# STM32H7R3xx register map
File version: 1.0
Registers are 32-bit, read-write, reset 0x0 unless marked. A register's access mark holds for its fields unless they carry their own. Offsets are from the block's base; [hi:lo] are bit positions; {n}, {i} and the like mark numbered series.

## HASH
Base 0x48020400
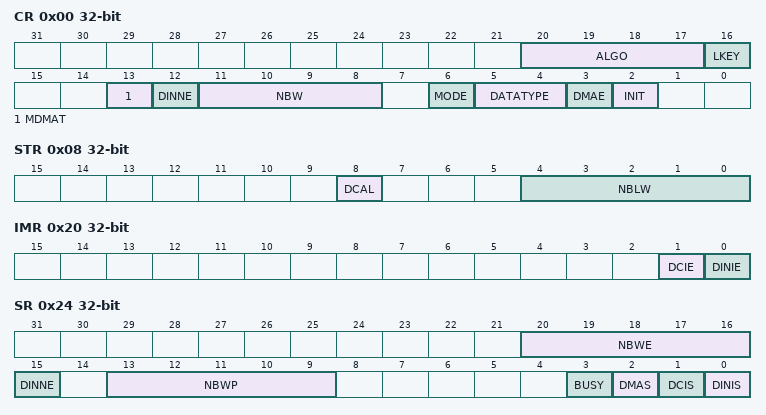
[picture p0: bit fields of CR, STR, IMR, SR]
0x00 CR — HASH control register
  [20:17] ALGO, [16] LKEY, [13] MDMAT, [12] DINNE, [11:8] NBW, [6] MODE, [5:4] DATATYPE, [3] DMAE, [2] INIT
0x04 DIN — HASH data input register
0x08 STR — HASH start register
  [8] DCAL, [4:0] NBLW
{0xC+4i} HR{i} (i=0..4) — HASH digest registers
0x20 IMR — HASH interrupt enable register
  [1] DCIE, [0] DINIE
0x24 SR — HASH status register
  [20:16] NBWE, [15] DINNE, [13:9] NBWP, [3] BUSY, [2] DMAS, [1] DCIS, [0] DINIS
{0xF8+4i} CSR[{i}] (i=0..102)
{0x310+4i} DIGEST_HR{i} (i=0..15) — HASH digest registers

## PKA — Public Key Accelerator (PKA)
Base 0x48022000
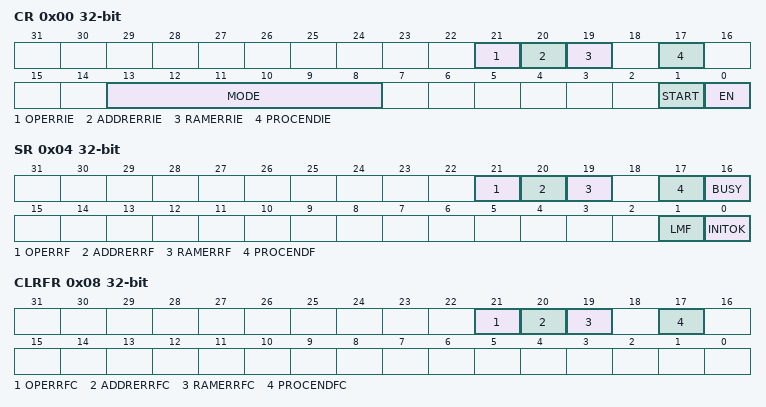
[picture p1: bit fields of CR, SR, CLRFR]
0x00 CR — PKA control register
  [21] OPERRIE — Operation Error interrupt enable
  [20] ADDRERRIE — Address error interrupt enable
  [19] RAMERRIE — RAM error interrupt enable
  [17] PROCENDIE — End of operation interrupt enable
  [13:8] MODE — MODE[5:0] PKA operation code
  [1] START — Start operation
  [0] EN — PKA enable
0x04 SR — PKA status register
  [21] OPERRF — PKA operation Error flag
  [20] ADDRERRF — Address error flag
  [19] RAMERRF — PKA RAM error flag
  [17] PROCENDF — PKA end of operation flag
  [16] BUSY — PKA operation is in progress
  [1] LMF — Limited mode flag
  [0] INITOK — PKA initialisation flag
0x08 CLRFR — PKA clear flag register
  [21] OPERRFC — Clear PKA operation Error flag
  [20] ADDRERRFC — Clear address error flag
  [19] RAMERRFC — Clear PKA RAM error flag
  [17] PROCENDFC — Clear PKA end of operation flag
{0x400+4i} RAM[{i}] (i=0..1333)

## GFXTIM
Base 0x50004000
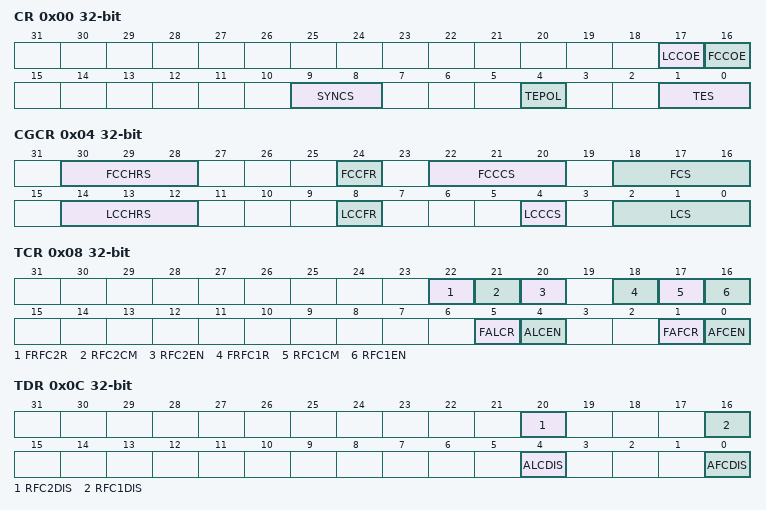
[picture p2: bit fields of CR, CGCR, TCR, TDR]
0x00 CR — GFXTIM configuration register
  [17] LCCOE, [16] FCCOE, [9:8] SYNCS, [4] TEPOL, [1:0] TES
0x04 CGCR — GFXTIM clock generator configuration register
  [30:28] FCCHRS, [24] FCCFR, [22:20] FCCCS, [18:16] FCS, [14:12] LCCHRS, [8] LCCFR, [4] LCCCS, [2:0] LCS
0x08 TCR — GFXTIM timers configuration register
  [22] FRFC2R, [21] RFC2CM, [20] RFC2EN, [18] FRFC1R, [17] RFC1CM, [16] RFC1EN, [5] FALCR, [4] ALCEN, [1] FAFCR, [0] AFCEN
0x0C TDR — GFXTIM timers disable register
  [20] RFC2DIS, [16] RFC1DIS, [4] ALCDIS, [0] AFCDIS
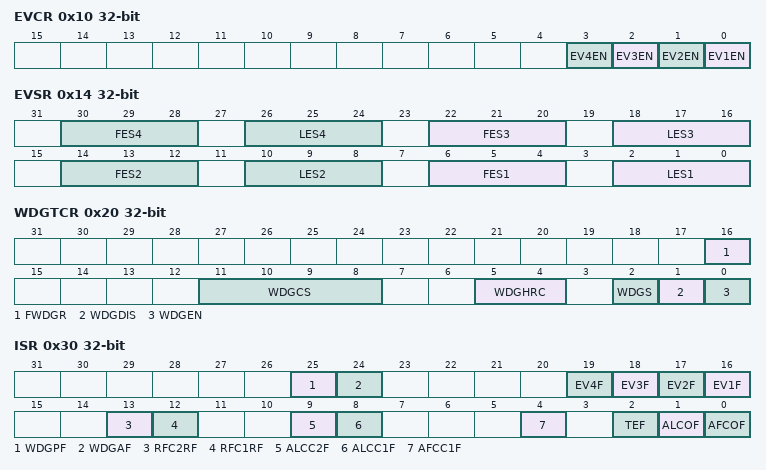
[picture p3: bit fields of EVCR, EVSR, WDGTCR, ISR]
0x10 EVCR — GFXTIM events control register
  [n-1] EV{n}EN (n=1..4)
0x14 EVSR — GFXTIM events selection register
  [8n-2:8n-4] FES{n} (n=1..4), [8n-6:8n-8] LES{n} (n=1..4)
0x20 WDGTCR — GFXTIM watchdog timer configuration register
  [16] FWDGR, [11:8] WDGCS, [5:4] WDGHRC, [2] WDGS, [1] WDGDIS, [0] WDGEN
0x30 ISR — GFXTIM interrupt status register
  [25] WDGPF, [24] WDGAF, [n+15] EV{n}F (n=1..4), [13] RFC2RF, [12] RFC1RF, [9] ALCC2F, [8] ALCC1F, [4] AFCC1F, [2] TEF, [1] ALCOF, [0] AFCOF
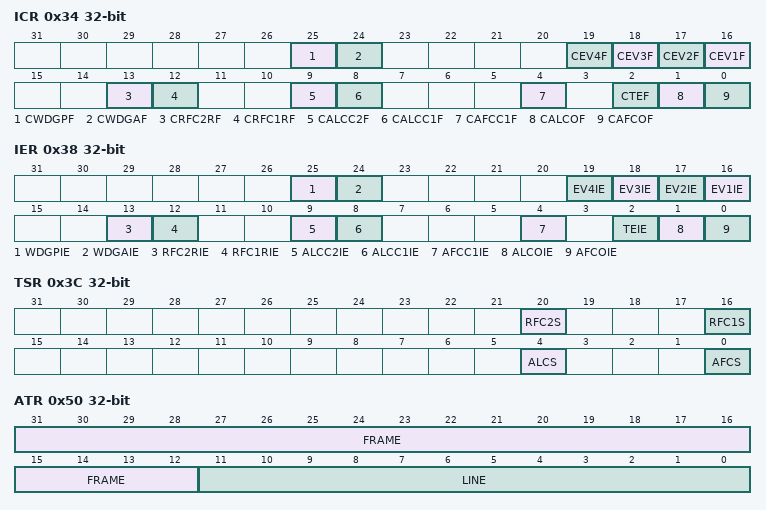
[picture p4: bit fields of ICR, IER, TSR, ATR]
0x34 ICR — GFXTIM interrupt clear register
  [25] CWDGPF, [24] CWDGAF, [n+15] CEV{n}F (n=1..4), [13] CRFC2RF, [12] CRFC1RF, [9] CALCC2F, [8] CALCC1F, [4] CAFCC1F, [2] CTEF, [1] CALCOF, [0] CAFCOF
0x38 IER — GFXTIM interrupt enable register
  [25] WDGPIE, [24] WDGAIE, [n+15] EV{n}IE (n=1..4), [13] RFC2RIE, [12] RFC1RIE, [9] ALCC2IE, [8] ALCC1IE, [4] AFCC1IE, [2] TEIE, [1] ALCOIE, [0] AFCOIE
0x3C TSR — GFXTIM timers status register
  [20] RFC2S, [16] RFC1S, [4] ALCS, [0] AFCS
0x40 LCCRR — GFXTIM line clock counter reload register
  [21:0] RELOAD
0x44 FCCRR — GFXTIM frame clock counter reload register
  [11:0] RELOAD
0x50 ATR — GFXTIM absolute time register
  [31:12] FRAME, [11:0] LINE
0x54 AFCR — GFXTIM absolute frame counter register
  [19:0] FRAME
0x58 ALCR — GFXTIM absolute line counter register
  [11:0] LINE
0x60 AFCC1R — GFXTIM absolute frame counter compare 1 register
  [19:0] FRAME
0x70 ALCC1R — GFXTIM absolute line counter compare 1 register
  [11:0] LINE
0x74 ALCC2R — GFXTIM absolute line counter compare 2 register
  [11:0] LINE
0x80 RFC1R — GFXTIM relative frame counter 1 register
  [11:0] FRAME
0x84 RFC1RR — GFXTIM relative frame counter 1 reload register
  [11:0] FRAME
0x88 RFC2R — GFXTIM relative frame counter 2 register
  [11:0] FRAME
0x8C RFC2RR — GFXTIM relative frame counter 2 reload register
  [11:0] FRAME
0xA0 WDGCR — GFXTIM watchdog counter register
  [15:0] VALUE
0xA4 WDGRR — GFXTIM watchdog reload register
  [15:0] RELOAD
0xA8 WDGPAR — GFXTIM watchdog pre-alarm register
  [15:0] PREALARM
0x3F0 HWCFGR — GFXTIM HW configuration register
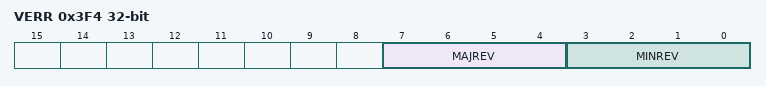
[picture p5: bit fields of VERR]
0x3F4 VERR — GFXTIM version register
  [7:4] MAJREV, [3:0] MINREV
0x3F8 IPIDR — GFXTIM identification register
  [31:0] ID
0x3FC SIDR — GFXTIM size identification register
  [31:0] SID
